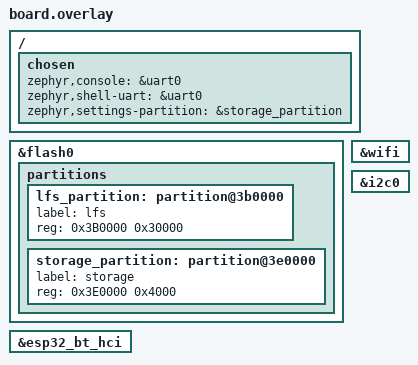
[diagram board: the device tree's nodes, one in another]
/*
 * SPDX-License-Identifier: MIT
 * TTGO LoRa32 — ZephCore overlay
 *
 * The upstream Zephyr DTS (ttgo_lora32_esp32_procpu.dts) already defines:
 *   SX1276 on SPI3 (NSS=GPIO18, SCK/MOSI/MISO via pinctrl)
 *   SSD1306 OLED on I2C0 (SDA=GPIO21, SCL=GPIO22)
 *   UART0 console (TX=GPIO1, RX=GPIO3)
 *   LED0 on GPIO25, WiFi
 *
 * LoRa SPI3 pins: NSS=18, DIO0=26, DIO1=35, DIO2=34
 * LoRa control:   RESET=23
 * Display I2C0:   SDA=21, SCL=22 (SSD1306 @ 0x3C)
 *
 * Flash layout (partitions_0x1000_amp_4M.dtsi):
 *   storage_partition @ 0x3B0000 (192KB) — repurposed as LittleFS
 */

/ {
	chosen {
		/* UART0 console is correct for classic ESP32 (no native USB) */
		zephyr,console = &uart0;
		zephyr,shell-uart = &uart0;
	};
};

/*
 * Flash partitions — repurpose storage_partition as LittleFS.
 * The 4MB layout has appcpu slots we don't use (procpu-only build),
 * but we leave them to avoid changing the partition map.
 */
/delete-node/ &storage_partition;
/delete-node/ &scratch_partition;

/ {
	chosen {
		zephyr,settings-partition = &storage_partition;
	};
};

&flash0 {
	partitions {
		/* LittleFS 192KB for DataStore (identity, prefs, creds) */
		lfs_partition: partition@3b0000 {
			label = "lfs";
			reg = <0x3B0000 0x30000>;
		};
		/* BLE bond store — 16KB NVS, isolated from /lfs (see esp32_common.conf).
		 * Placed in the unused scratch region just above lfs (lfs unchanged). */
		storage_partition: partition@3e0000 {
			label = "storage";
			reg = <0x3E0000 0x4000>;
		};
	};
};

/* LittleFS auto-mount — standard /lfs mount point */
#include "../../common/filesystem.dtsi"

/* WiFi — required for observer MQTT connectivity */
&wifi {
	status = "okay";
};

/*
 * BT HCI controller — the upstream ttgo_lora32 DTS leaves the node disabled
 * (esp32_common.dtsi already sets chosen zephyr,bt-hci to it).  Companion
 * builds set CONFIG_BT=y, and the hal_espressif CMake compiles the ESP32 BT
 * controller under CONFIG_BT alone; without this node BT_ESP32 stays off and
 * its Kconfig symbols (CONFIG_ESP32_BT_CONTROLLER_TASK_PRIO etc.) are
 * undefined, breaking the bt.c compile.  Same fix as ttgo_tbeam.
 */
&esp32_bt_hci {
	status = "okay";
};

/* I2C sensors — auto-detected at runtime */
&i2c0 {
	#include "../../common/sensors-i2c.dtsi"
};
